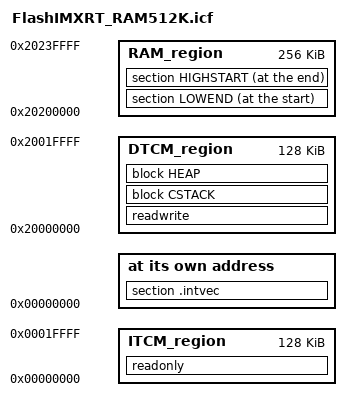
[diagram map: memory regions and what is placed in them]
/*###ICF### Section handled by ICF editor, don't touch! ****/
/*-Editor annotation file-*/
/* IcfEditorFile="$TOOLKIT_DIR$\config\ide\IcfEditor\cortex_v1_0.xml" */
/*-Specials-*/
define symbol __ICFEDIT_intvec_start__ = 0x00000000;
/*-Memory Regions-*/
define symbol __ICFEDIT_region_ROM_start__   = 0x00000000;
define symbol __ICFEDIT_region_ROM_end__     = 0x00000000;
define symbol __ICFEDIT_region_RAM_start__   = 0x20200000;
define symbol __ICFEDIT_region_RAM_end__     = 0x2023FFFF;
/*-Sizes-*/
define symbol __ICFEDIT_size_cstack__   = 0x1000;
define symbol __ICFEDIT_size_heap__     = 0x100;
/**** End of ICF editor section. ###ICF###*/

define symbol __region_ITCM_start__   = 0x00000000;
define symbol __region_ITCM_end__     = 0x0001FFFF;

define symbol __region_DTCM_start__   = 0x20000000;
define symbol __region_DTCM_end__     = 0x2001FFFF;

define memory mem with size = 4G;
define region ITCM_region = mem:[from __region_ITCM_start__ to __region_ITCM_end__];
define region DTCM_region = mem:[from __region_DTCM_start__ to __region_DTCM_end__];
define region RAM_region  = mem:[from __ICFEDIT_region_RAM_start__   to __ICFEDIT_region_RAM_end__];

define block CSTACK    with alignment = 8, size = __ICFEDIT_size_cstack__   { };
define block HEAP      with alignment = 8, size = __ICFEDIT_size_heap__     { };

do not initialize { zi };

place at address mem:__ICFEDIT_intvec_start__ { section .intvec };

place in ITCM_region { readonly };
place in DTCM_region { readwrite, block CSTACK, block HEAP };
place at start of RAM_region {section LOWEND};
place at end of RAM_region   {section HIGHSTART};
